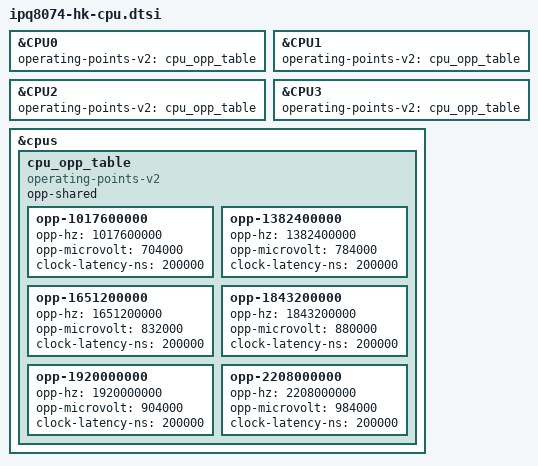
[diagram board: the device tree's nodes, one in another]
// SPDX-License-Identifier: GPL-2.0-only

&CPU0 {
	operating-points-v2 = <&cpu_opp_table>;
};

&CPU1 {
	operating-points-v2 = <&cpu_opp_table>;
};

&CPU2 {
	operating-points-v2 = <&cpu_opp_table>;
};

&CPU3 {
	operating-points-v2 = <&cpu_opp_table>;
};

&cpus {
	cpu_opp_table: cpu_opp_table {
		compatible = "operating-points-v2";
		opp-shared;

		opp-1017600000 {
			opp-hz = /bits/ 64 <1017600000>;
			opp-microvolt = <704000>;
			clock-latency-ns = <200000>;
		};
		opp-1382400000 {
			opp-hz = /bits/ 64 <1382400000>;
			opp-microvolt = <784000>;
			clock-latency-ns = <200000>;
		};
		opp-1651200000 {
			opp-hz = /bits/ 64 <1651200000>;
			opp-microvolt = <832000>;
			clock-latency-ns = <200000>;
		};
		opp-1843200000 {
			opp-hz = /bits/ 64 <1843200000>;
			opp-microvolt = <880000>;
			clock-latency-ns = <200000>;
		};
		opp-1920000000 {
			opp-hz = /bits/ 64 <1920000000>;
			opp-microvolt = <904000>;
			clock-latency-ns = <200000>;
		};
		opp-2208000000 {
			opp-hz = /bits/ 64 <2208000000>;
			opp-microvolt = <984000>;
			clock-latency-ns = <200000>;
		};
	};
};
